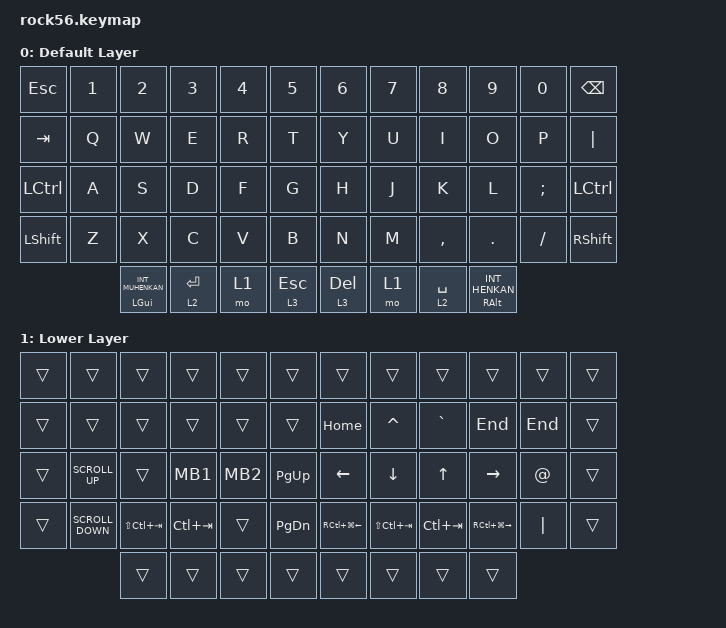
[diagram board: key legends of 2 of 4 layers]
/*
 * Copyright (c) 2020 The ZMK Contributors
 *
 * SPDX-License-Identifier: MIT
 */

#include <behaviors.dtsi>
#include <dt-bindings/zmk/keys.h>
#include <dt-bindings/zmk/bt.h>
#include <dt-bindings/zmk/pointing.h>

/ {
    keymap {
        compatible = "zmk,keymap";

        default_layer {
            display-name = "Default Layer";
/*
------------------------------------------------------------------------------------------------------------
| ESC    |  1    |  2                |  3        |  4   |  5      |     |  6      |  7   |  8        |  9                |  0     |  BS  |
| TAB    |  Q    |  W                |  E        |  R   |  T      |     |  Y      |  U   |  I        |  O                |  P     |  |   |
| CTRL   |  A    |  S                |  D        |  F   |  G      |     |  H      |  J   |  K        |  L                |  ;     | CTRL |
|SHIFT   |  Z    |  X                |  C        |  V   |  B      |     |  N      |  M   |  ,        |  .                |  /     |SHIFT |
                 | GUI/無変換        | RAISE/RET |LOWER | MID/ESC |     | MID/DEL |LOWER |RAISE/SPACE| ALT/変換          |
*/
            bindings = <
&kp ESC   &kp N1 &kp N2                &kp N3    &kp N4 &kp N5          &kp N6    &kp N7 &kp N8      &kp N9              &kp N0   &kp BSPC
&kp TAB   &kp Q  &kp W                 &kp E     &kp R  &kp T           &kp Y     &kp U  &kp I       &kp O               &kp P    &kp PIPE
&kp LCTRL &kp A  &kp S                 &kp D     &kp F  &kp G           &kp H     &kp J  &kp K       &kp L               &kp SEMI &kp LCTRL
&kp LSHFT &kp Z  &kp X                 &kp C     &kp V  &kp B           &kp N     &kp M  &kp COMMA   &kp DOT             &kp FSLH &kp RSHFT
                 &mt LGUI INT_MUHENKAN &lt 2 RET &mo 1  &lt 3 ESC       &lt 3 DEL &mo 1  &lt 2 SPACE &mt RALT INT_HENKAN
            >;
        };

        lower_layer {
            display-name = "Lower Layer";
/*
------------------------------------------------------------------------------------------------------------
|      |             |      |       |       |      |     |        |         |         |        |        |      |
|      |             |      |       |       |      |     | HOME   |   ^     |   `     |  END   |        |      |
|      |SCRL_UP      |      | MB1   | MB2   |PG_UP |     |  ←    |  ↓     |  ↑     |  →    |  @     |      |
|      |SCRL_DOWN    |      |S-C-Tab| S-Tab |PG_DN |     |        |         |         |        | "|"    |      |
                     |      |       |       |      |     |        |         |
*/
            bindings = <
&trans &trans            &trans          &trans      &trans  &trans       &trans           &trans          &trans      &trans            &trans   &trans
&trans &trans            &trans          &trans      &trans  &trans       &kp HOME         &kp CARET       &kp GRAVE   &kp END           &kp END  &trans
&trans &kp K_SCROLL_UP   &trans          &kp MB1     &kp MB2 &kp PG_UP    &kp LEFT         &kp DOWN        &kp UP      &kp RIGHT         &kp AT   &trans
&trans &kp K_SCROLL_DOWN &kp LS(LC(TAB)) &kp LC(TAB) &trans  &kp PG_DN    &kp RC(LG(LEFT)) &kp LS(LC(TAB)) &kp LC(TAB) &kp RC(LG(RIGHT)) &kp PIPE &trans
                         &trans          &trans      &trans  &trans       &trans           &trans          &trans      &trans
            >;
        };

        raise_layer {
            display-name = "Raise Layer";
/*
------------------------------------------------------------------------------------------------------------
|      |         |         |         |         |      |     |        |         |        |        |         |      |
|      |  1      |  2      |  3      |  4      |  5   |     |  6     |   7     |   8    |  9     |   0     |  `   |
|      |  !      |  "      |  #      |  $      |  %   |     |  &     |   '     |   [    |  ]     |   :     |      |
|      |  ~      |  _      |  =      |  -      |  ?   |     |  +     |   -     |   {    |  }     |   \     |      |
                 |         |         |         |      |     |        |         |        |        |
*/
            bindings = <
&trans &trans    &trans    &trans    &trans    &trans       &trans   &trans    &trans   &trans   &trans    &trans
&trans &kp N1    &kp N2    &kp N3    &kp N4    &kp N5       &kp N6   &kp N7    &kp N8   &kp N9   &kp N0    &kp GRAVE
&trans &kp EXCL  &kp DQT   &kp HASH  &kp DLLR  &kp PRCNT    &kp AMPS &kp SQT   &kp LBKT &kp RBKT &kp COLON &trans
&trans &kp TILDE &kp MINUS &kp EQUAL &kp UNDER &kp QMARK    &kp PLUS &kp LBRC  &kp RBRC &kp BSLH &trans   &trans
                             &trans  &trans    &trans       &trans   &trans    &trans   &trans
            >;
        };

        middle_layer {
            display-name = "Middle Layer";
/*
------------------------------------------------------------------------------------------------------------
|      |         |         |         |         |      |     |        |         |        |        |         |      |
|      |  1      |  2      |  3      |  4      |  5   |     |  6     |   7     |   8    |  9     |   0     |  `   |
|      |  !      |  "      |  #      |  $      |  %   |     |  &     |   '     |   [    |  ]     |   :     |      |
|      |  ~      |  _      |  =      |  -      |  ?   |     |  +     |   -     |   {    |  }     |   \     |      |
                 |         |         |         |      |     |        |         |        |        |
*/
            bindings = <
&trans &trans    &trans    &trans    &trans        &trans                       &trans   &trans        &trans        &trans   &trans     &trans
&trans &kp F1    &kp F2    &kp F3    &kp F4        &kp F5                       &kp F6   &kp F7        &kp F8        &kp F9   &kp F10    &trans
&trans &trans    &trans    &trans    &kp LC(PLUS)  &kp LANG_ZENKAKUHANKAKU      &trans   &kp LC(PG_DN) &kp LC(PG_UP) &trans   &kp F11    &trans
&trans &trans    &trans    &trans    &kp LC(MINUS) &kp K_APP                    &trans   &trans        &trans        &trans   &kp F12    &trans
                           &trans    &trans        &trans                       &trans   &trans        &trans        &trans
            >;
        };
    };
};
